VERSION ""

NS_ :

BS_:

BU_:

BO_ 1 counter: 4 Vector__XXX
 SG_ counter : 0|32@1+ (1,0) [0|0] "" Vector__XXX

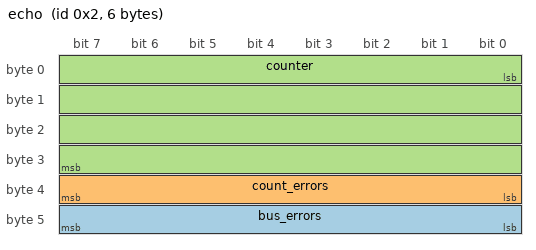
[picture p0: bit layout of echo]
BO_ 2 echo: 6 Vector__XXX
 SG_ bus_errors : 40|8@1+ (1,0) [0|0] "" Vector__XXX
 SG_ count_errors : 32|8@1+ (1,0) [0|0] "" Vector__XXX
 SG_ counter : 0|32@1+ (1,0) [0|0] "" Vector__XXX
